# ESP32-S3 register map
Vendor: ESPRESSIF SYSTEMS (SHANGHAI) CO., LTD.; Series: ESP32-S3; File version: 7
CPU: Xtensa LX7 r0p0, little endian, no MPU, FPU, 3 interrupt priority bits
Address unit: 32 bits
Registers are 32-bit, read-write, reset 0x0 unless marked. A register's access mark holds for its fields unless they carry their own. Offsets are from the block's base; [hi:lo] are bit positions; {n}, {i} and the like mark numbered series.

## DMA — DMA (Direct Memory Access) Controller
Base 0x6003F000
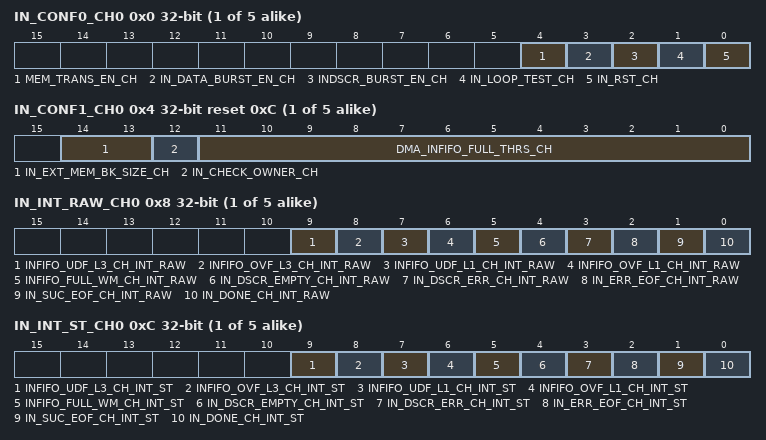
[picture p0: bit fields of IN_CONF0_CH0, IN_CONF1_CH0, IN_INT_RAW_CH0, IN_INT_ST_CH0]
{0x0+0xC0*i} IN_CONF0_CH{i} (i=0..4) — Configure 0 register of Rx channel 0
  [4] MEM_TRANS_EN_CH — Set this bit 1 to enable automatic transmitting data from memory to memory via DMA.
  [3] IN_DATA_BURST_EN_CH — Set this bit to 1 to enable INCR burst transfer for Rx channel 0 receiving data when accessing internal SRAM.
  [2] INDSCR_BURST_EN_CH — Set this bit to 1 to enable INCR burst transfer for Rx channel 0 reading link descriptor when accessing internal SRAM.
  [1] IN_LOOP_TEST_CH — reserved
  [0] IN_RST_CH — This bit is used to reset DMA channel 0 Rx FSM and Rx FIFO pointer.
{0x4+0xC0*i} IN_CONF1_CH{i} (i=0..4) reset 0xC — Configure 1 register of Rx channel 0
  [14:13] IN_EXT_MEM_BK_SIZE_CH — Block size of Rx channel 0 when DMA access external SRAM. 0: 16 bytes 1: 32 bytes 2/3:reserved
  [12] IN_CHECK_OWNER_CH — Set this bit to enable checking the owner attribute of the link descriptor.
  [11:0] DMA_INFIFO_FULL_THRS_CH — This register is used to generate the INFIFO_FULL_WM_INT interrupt when Rx channel 0 received byte number in Rx FIFO is up to the value of the register.
{0x8+0xC0*i} IN_INT_RAW_CH{i} (i=0..4) ro — Raw status interrupt of Rx channel 0
  [9] INFIFO_UDF_L3_CH_INT_RAW — This raw interrupt bit turns to high level when level 3 fifo of Rx channel 0 is underflow.
  [8] INFIFO_OVF_L3_CH_INT_RAW — This raw interrupt bit turns to high level when level 3 fifo of Rx channel 0 is overflow.
  [7] INFIFO_UDF_L1_CH_INT_RAW — This raw interrupt bit turns to high level when level 1 fifo of Rx channel 0 is underflow.
  [6] INFIFO_OVF_L1_CH_INT_RAW — This raw interrupt bit turns to high level when level 1 fifo of Rx channel 0 is overflow.
  [5] INFIFO_FULL_WM_CH_INT_RAW — The raw interrupt bit turns to high level when received data byte number is up to threshold configured by REG_DMA_INFIFO_FULL_THRS_CH0 in Rx FIFO of channel 0.
  [4] IN_DSCR_EMPTY_CH_INT_RAW — The raw interrupt bit turns to high level when Rx buffer pointed by inlink is full and receiving data is not completed, but there is no more inlink for Rx channel 0.
  [3] IN_DSCR_ERR_CH_INT_RAW — The raw interrupt bit turns to high level when detecting inlink descriptor error, including owner error, the second and third word error of inlink descriptor for Rx channel 0.
  [2] IN_ERR_EOF_CH_INT_RAW — The raw interrupt bit turns to high level when data error is detected only in the case that the peripheral is UHCI0 for Rx channel 0. For other peripherals, this raw interrupt is reserved.
  [1] IN_SUC_EOF_CH_INT_RAW — The raw interrupt bit turns to high level when the last data pointed by one inlink descriptor has been received for Rx channel 0. For UHCI0, the raw interrupt bit turns to high level when the last data pointed by one inlink descriptor has been received and no data error is detected for Rx channel 0.
  [0] IN_DONE_CH_INT_RAW — The raw interrupt bit turns to high level when the last data pointed by one inlink descriptor has been received for Rx channel 0.
{0xC+0xC0*i} IN_INT_ST_CH{i} (i=0..4) ro — Masked interrupt of Rx channel 0
  [9] INFIFO_UDF_L3_CH_INT_ST — The raw interrupt status bit for the INFIFO_UDF_L3_CH_INT interrupt.
  [8] INFIFO_OVF_L3_CH_INT_ST — The raw interrupt status bit for the INFIFO_OVF_L3_CH_INT interrupt.
  [7] INFIFO_UDF_L1_CH_INT_ST — The raw interrupt status bit for the INFIFO_UDF_L1_CH_INT interrupt.
  [6] INFIFO_OVF_L1_CH_INT_ST — The raw interrupt status bit for the INFIFO_OVF_L1_CH_INT interrupt.
  [5] INFIFO_FULL_WM_CH_INT_ST — The raw interrupt status bit for the INFIFO_FULL_WM_CH_INT interrupt.
  [4] IN_DSCR_EMPTY_CH_INT_ST — The raw interrupt status bit for the IN_DSCR_EMPTY_CH_INT interrupt.
  [3] IN_DSCR_ERR_CH_INT_ST — The raw interrupt status bit for the IN_DSCR_ERR_CH_INT interrupt.
  [2] IN_ERR_EOF_CH_INT_ST — The raw interrupt status bit for the IN_ERR_EOF_CH_INT interrupt.
  [1] IN_SUC_EOF_CH_INT_ST — The raw interrupt status bit for the IN_SUC_EOF_CH_INT interrupt.
  [0] IN_DONE_CH_INT_ST — The raw interrupt status bit for the IN_DONE_CH_INT interrupt.
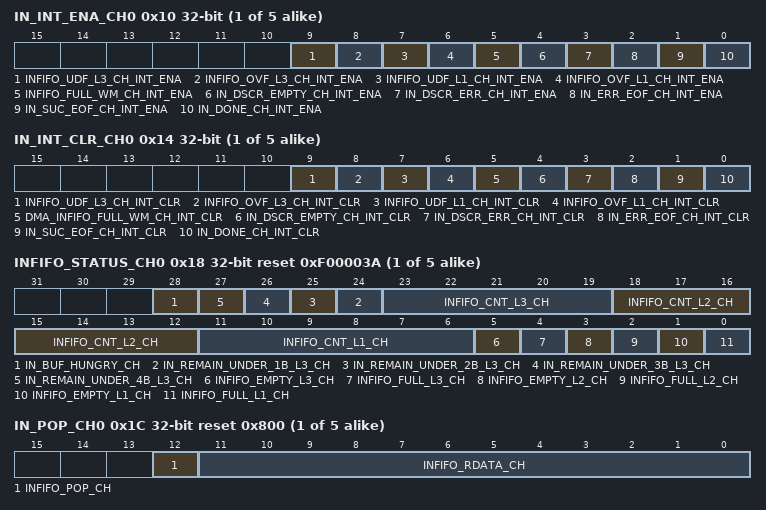
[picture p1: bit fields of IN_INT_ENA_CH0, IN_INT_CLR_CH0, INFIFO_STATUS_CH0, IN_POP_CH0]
{0x10+0xC0*i} IN_INT_ENA_CH{i} (i=0..4) — Interrupt enable bits of Rx channel 0
  [9] INFIFO_UDF_L3_CH_INT_ENA — The interrupt enable bit for the INFIFO_UDF_L3_CH_INT interrupt.
  [8] INFIFO_OVF_L3_CH_INT_ENA — The interrupt enable bit for the INFIFO_OVF_L3_CH_INT interrupt.
  [7] INFIFO_UDF_L1_CH_INT_ENA — The interrupt enable bit for the INFIFO_UDF_L1_CH_INT interrupt.
  [6] INFIFO_OVF_L1_CH_INT_ENA — The interrupt enable bit for the INFIFO_OVF_L1_CH_INT interrupt.
  [5] INFIFO_FULL_WM_CH_INT_ENA — The interrupt enable bit for the INFIFO_FULL_WM_CH_INT interrupt.
  [4] IN_DSCR_EMPTY_CH_INT_ENA — The interrupt enable bit for the IN_DSCR_EMPTY_CH_INT interrupt.
  [3] IN_DSCR_ERR_CH_INT_ENA — The interrupt enable bit for the IN_DSCR_ERR_CH_INT interrupt.
  [2] IN_ERR_EOF_CH_INT_ENA — The interrupt enable bit for the IN_ERR_EOF_CH_INT interrupt.
  [1] IN_SUC_EOF_CH_INT_ENA — The interrupt enable bit for the IN_SUC_EOF_CH_INT interrupt.
  [0] IN_DONE_CH_INT_ENA — The interrupt enable bit for the IN_DONE_CH_INT interrupt.
{0x14+0xC0*i} IN_INT_CLR_CH{i} (i=0..4) wo — Interrupt clear bits of Rx channel 0
  [9] INFIFO_UDF_L3_CH_INT_CLR — Set this bit to clear the INFIFO_UDF_L3_CH_INT interrupt.
  [8] INFIFO_OVF_L3_CH_INT_CLR — Set this bit to clear the INFIFO_OVF_L3_CH_INT interrupt.
  [7] INFIFO_UDF_L1_CH_INT_CLR — Set this bit to clear the INFIFO_UDF_L1_CH_INT interrupt.
  [6] INFIFO_OVF_L1_CH_INT_CLR — Set this bit to clear the INFIFO_OVF_L1_CH_INT interrupt.
  [5] DMA_INFIFO_FULL_WM_CH_INT_CLR — Set this bit to clear the INFIFO_FULL_WM_CH_INT interrupt.
  [4] IN_DSCR_EMPTY_CH_INT_CLR — Set this bit to clear the IN_DSCR_EMPTY_CH_INT interrupt.
  [3] IN_DSCR_ERR_CH_INT_CLR — Set this bit to clear the IN_DSCR_ERR_CH_INT interrupt.
  [2] IN_ERR_EOF_CH_INT_CLR — Set this bit to clear the IN_ERR_EOF_CH_INT interrupt.
  [1] IN_SUC_EOF_CH_INT_CLR — Set this bit to clear the IN_SUC_EOF_CH_INT interrupt.
  [0] IN_DONE_CH_INT_CLR — Set this bit to clear the IN_DONE_CH_INT interrupt.
{0x18+0xC0*i} INFIFO_STATUS_CH{i} (i=0..4) ro reset 0xF00003A — Receive FIFO status of Rx channel 0
  [28] IN_BUF_HUNGRY_CH — reserved
  [n+23] IN_REMAIN_UNDER_{n}B_L3_CH (n=1..4) — reserved
  [23:19] INFIFO_CNT_L3_CH — The register stores the byte number of the data in L3 Rx FIFO for Rx channel 0.
  [18:12] INFIFO_CNT_L2_CH — The register stores the byte number of the data in L2 Rx FIFO for Rx channel 0.
  [11:6] INFIFO_CNT_L1_CH — The register stores the byte number of the data in L1 Rx FIFO for Rx channel 0.
  [5] INFIFO_EMPTY_L3_CH — L3 Rx FIFO empty signal for Rx channel 0.
  [4] INFIFO_FULL_L3_CH — L3 Rx FIFO full signal for Rx channel 0.
  [3] INFIFO_EMPTY_L2_CH — L2 Rx FIFO empty signal for Rx channel 0.
  [2] INFIFO_FULL_L2_CH — L2 Rx FIFO full signal for Rx channel 0.
  [1] INFIFO_EMPTY_L1_CH — L1 Rx FIFO empty signal for Rx channel 0.
  [0] INFIFO_FULL_L1_CH — L1 Rx FIFO full signal for Rx channel 0.
{0x1C+0xC0*i} IN_POP_CH{i} (i=0..4) access per field reset 0x800 — Pop control register of Rx channel 0
  [12] INFIFO_POP_CH rw — Set this bit to pop data from DMA FIFO.
  [11:0] INFIFO_RDATA_CH ro — This register stores the data popping from DMA FIFO.
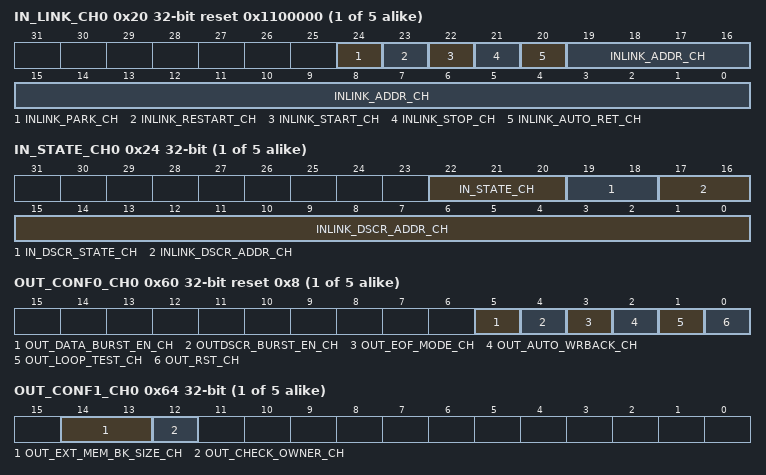
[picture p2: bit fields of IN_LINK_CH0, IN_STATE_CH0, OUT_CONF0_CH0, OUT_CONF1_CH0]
{0x20+0xC0*i} IN_LINK_CH{i} (i=0..4) access per field reset 0x1100000 — Link descriptor configure and control register of Rx channel 0
  [24] INLINK_PARK_CH ro — 1: the inlink descriptor's FSM is in idle state. 0: the inlink descriptor's FSM is working.
  [23] INLINK_RESTART_CH rw — Set this bit to mount a new inlink descriptor.
  [22] INLINK_START_CH rw — Set this bit to start dealing with the inlink descriptors.
  [21] INLINK_STOP_CH rw — Set this bit to stop dealing with the inlink descriptors.
  [20] INLINK_AUTO_RET_CH rw — Set this bit to return to current inlink descriptor's address, when there are some errors in current receiving data.
  [19:0] INLINK_ADDR_CH rw — This register stores the 20 least significant bits of the first inlink descriptor's address.
{0x24+0xC0*i} IN_STATE_CH{i} (i=0..4) ro — Receive status of Rx channel 0
  [22:20] IN_STATE_CH — reserved
  [19:18] IN_DSCR_STATE_CH — reserved
  [17:0] INLINK_DSCR_ADDR_CH — This register stores the current inlink descriptor's address.
{0x28+0xC0*i} IN_SUC_EOF_DES_ADDR_CH{i} (i=0..4) ro — Inlink descriptor address when EOF occurs of Rx channel 0
  [31:0] IN_SUC_EOF_DES_ADDR_CH — This register stores the address of the inlink descriptor when the EOF bit in this descriptor is 1.
{0x2C+0xC0*i} IN_ERR_EOF_DES_ADDR_CH{i} (i=0..4) ro — Inlink descriptor address when errors occur of Rx channel 0
  [31:0] IN_ERR_EOF_DES_ADDR_CH — This register stores the address of the inlink descriptor when there are some errors in current receiving data. Only used when peripheral is UHCI0.
{0x30+0xC0*i} IN_DSCR_CH{i} (i=0..4) ro — Current inlink descriptor address of Rx channel 0
  [31:0] INLINK_DSCR_CH — The address of the current inlink descriptor x.
{0x34+0xC0*i} IN_DSCR_BF0_CH{i} (i=0..4) ro — The last inlink descriptor address of Rx channel 0
  [31:0] INLINK_DSCR_BF0_CH — The address of the last inlink descriptor x-1.
{0x38+0xC0*i} IN_DSCR_BF1_CH{i} (i=0..4) ro — The second-to-last inlink descriptor address of Rx channel 0
  [31:0] INLINK_DSCR_BF1_CH — The address of the second-to-last inlink descriptor x-2.
{0x3C+0xC0*i} IN_WIGHT_CH{i} (i=0..4) reset 0xF00 — Weight register of Rx channel 0
  [11:8] RX_WEIGHT_CH — The weight of Rx channel 0.
{0x44+0xC0*i} IN_PRI_CH{i} (i=0..4) — Priority register of Rx channel 0
  [3:0] RX_PRI_CH — The priority of Rx channel 0. The larger of the value, the higher of the priority.
{0x48+0xC0*i} IN_PERI_SEL_CH{i} (i=0..4) reset 0x3F — Peripheral selection of Rx channel 0
  [5:0] PERI_IN_SEL_CH — This register is used to select peripheral for Rx channel 0. 0:SPI2. 1: SPI3. 2: UHCI0. 3: I2S0. 4: I2S1. 5: LCD_CAM. 6: AES. 7: SHA. 8: ADC_DAC. 9: RMT.
{0x60+0xC0*i} OUT_CONF0_CH{i} (i=0..4) reset 0x8 — Configure 0 register of Tx channel 0
  [5] OUT_DATA_BURST_EN_CH — Set this bit to 1 to enable INCR burst transfer for Tx channel 0 transmitting data when accessing internal SRAM.
  [4] OUTDSCR_BURST_EN_CH — Set this bit to 1 to enable INCR burst transfer for Tx channel 0 reading link descriptor when accessing internal SRAM.
  [3] OUT_EOF_MODE_CH — EOF flag generation mode when transmitting data. 1: EOF flag for Tx channel 0 is generated when data need to transmit has been popped from FIFO in DMA
  [2] OUT_AUTO_WRBACK_CH — Set this bit to enable automatic outlink-writeback when all the data in tx buffer has been transmitted.
  [1] OUT_LOOP_TEST_CH — reserved
  [0] OUT_RST_CH — This bit is used to reset DMA channel 0 Tx FSM and Tx FIFO pointer.
{0x64+0xC0*i} OUT_CONF1_CH{i} (i=0..4) — Configure 1 register of Tx channel 0
  [14:13] OUT_EXT_MEM_BK_SIZE_CH — Block size of Tx channel 0 when DMA access external SRAM. 0: 16 bytes 1: 32 bytes 2/3:reserved
  [12] OUT_CHECK_OWNER_CH — Set this bit to enable checking the owner attribute of the link descriptor.
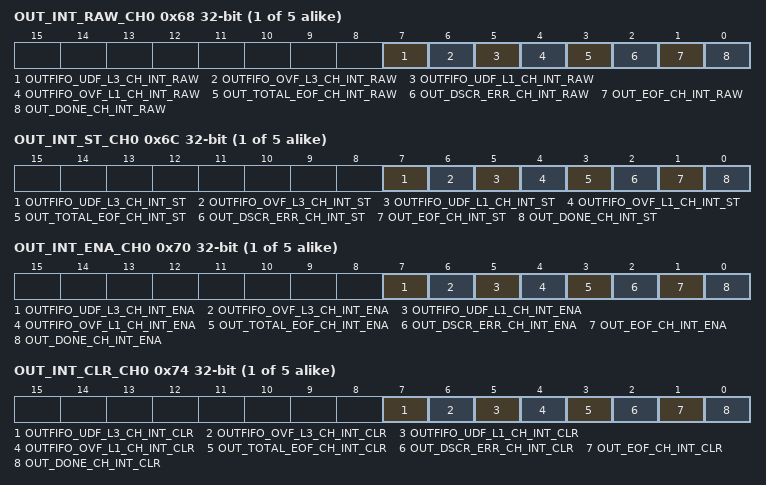
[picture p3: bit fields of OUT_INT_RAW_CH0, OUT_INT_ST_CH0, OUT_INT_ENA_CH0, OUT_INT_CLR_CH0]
{0x68+0xC0*i} OUT_INT_RAW_CH{i} (i=0..4) ro — Raw status interrupt of Tx channel 0
  [7] OUTFIFO_UDF_L3_CH_INT_RAW — This raw interrupt bit turns to high level when level 3 fifo of Tx channel 0 is underflow.
  [6] OUTFIFO_OVF_L3_CH_INT_RAW — This raw interrupt bit turns to high level when level 3 fifo of Tx channel 0 is overflow.
  [5] OUTFIFO_UDF_L1_CH_INT_RAW — This raw interrupt bit turns to high level when level 1 fifo of Tx channel 0 is underflow.
  [4] OUTFIFO_OVF_L1_CH_INT_RAW — This raw interrupt bit turns to high level when level 1 fifo of Tx channel 0 is overflow.
  [3] OUT_TOTAL_EOF_CH_INT_RAW — The raw interrupt bit turns to high level when data corresponding a outlink (includes one link descriptor or few link descriptors) is transmitted out for Tx channel 0.
  [2] OUT_DSCR_ERR_CH_INT_RAW — The raw interrupt bit turns to high level when detecting outlink descriptor error, including owner error, the second and third word error of outlink descriptor for Tx channel 0.
  [1] OUT_EOF_CH_INT_RAW — The raw interrupt bit turns to high level when the last data pointed by one outlink descriptor has been read from memory for Tx channel 0.
  [0] OUT_DONE_CH_INT_RAW — The raw interrupt bit turns to high level when the last data pointed by one outlink descriptor has been transmitted to peripherals for Tx channel 0.
{0x6C+0xC0*i} OUT_INT_ST_CH{i} (i=0..4) ro — Masked interrupt of Tx channel 0
  [7] OUTFIFO_UDF_L3_CH_INT_ST — The raw interrupt status bit for the OUTFIFO_UDF_L3_CH_INT interrupt.
  [6] OUTFIFO_OVF_L3_CH_INT_ST — The raw interrupt status bit for the OUTFIFO_OVF_L3_CH_INT interrupt.
  [5] OUTFIFO_UDF_L1_CH_INT_ST — The raw interrupt status bit for the OUTFIFO_UDF_L1_CH_INT interrupt.
  [4] OUTFIFO_OVF_L1_CH_INT_ST — The raw interrupt status bit for the OUTFIFO_OVF_L1_CH_INT interrupt.
  [3] OUT_TOTAL_EOF_CH_INT_ST — The raw interrupt status bit for the OUT_TOTAL_EOF_CH_INT interrupt.
  [2] OUT_DSCR_ERR_CH_INT_ST — The raw interrupt status bit for the OUT_DSCR_ERR_CH_INT interrupt.
  [1] OUT_EOF_CH_INT_ST — The raw interrupt status bit for the OUT_EOF_CH_INT interrupt.
  [0] OUT_DONE_CH_INT_ST — The raw interrupt status bit for the OUT_DONE_CH_INT interrupt.
{0x70+0xC0*i} OUT_INT_ENA_CH{i} (i=0..4) — Interrupt enable bits of Tx channel 0
  [7] OUTFIFO_UDF_L3_CH_INT_ENA — The interrupt enable bit for the OUTFIFO_UDF_L3_CH_INT interrupt.
  [6] OUTFIFO_OVF_L3_CH_INT_ENA — The interrupt enable bit for the OUTFIFO_OVF_L3_CH_INT interrupt.
  [5] OUTFIFO_UDF_L1_CH_INT_ENA — The interrupt enable bit for the OUTFIFO_UDF_L1_CH_INT interrupt.
  [4] OUTFIFO_OVF_L1_CH_INT_ENA — The interrupt enable bit for the OUTFIFO_OVF_L1_CH_INT interrupt.
  [3] OUT_TOTAL_EOF_CH_INT_ENA — The interrupt enable bit for the OUT_TOTAL_EOF_CH_INT interrupt.
  [2] OUT_DSCR_ERR_CH_INT_ENA — The interrupt enable bit for the OUT_DSCR_ERR_CH_INT interrupt.
  [1] OUT_EOF_CH_INT_ENA — The interrupt enable bit for the OUT_EOF_CH_INT interrupt.
  [0] OUT_DONE_CH_INT_ENA — The interrupt enable bit for the OUT_DONE_CH_INT interrupt.
{0x74+0xC0*i} OUT_INT_CLR_CH{i} (i=0..4) wo — Interrupt clear bits of Tx channel 0
  [7] OUTFIFO_UDF_L3_CH_INT_CLR — Set this bit to clear the OUTFIFO_UDF_L3_CH_INT interrupt.
  [6] OUTFIFO_OVF_L3_CH_INT_CLR — Set this bit to clear the OUTFIFO_OVF_L3_CH_INT interrupt.
  [5] OUTFIFO_UDF_L1_CH_INT_CLR — Set this bit to clear the OUTFIFO_UDF_L1_CH_INT interrupt.
  [4] OUTFIFO_OVF_L1_CH_INT_CLR — Set this bit to clear the OUTFIFO_OVF_L1_CH_INT interrupt.
  [3] OUT_TOTAL_EOF_CH_INT_CLR — Set this bit to clear the OUT_TOTAL_EOF_CH_INT interrupt.
  [2] OUT_DSCR_ERR_CH_INT_CLR — Set this bit to clear the OUT_DSCR_ERR_CH_INT interrupt.
  [1] OUT_EOF_CH_INT_CLR — Set this bit to clear the OUT_EOF_CH_INT interrupt.
  [0] OUT_DONE_CH_INT_CLR — Set this bit to clear the OUT_DONE_CH_INT interrupt.
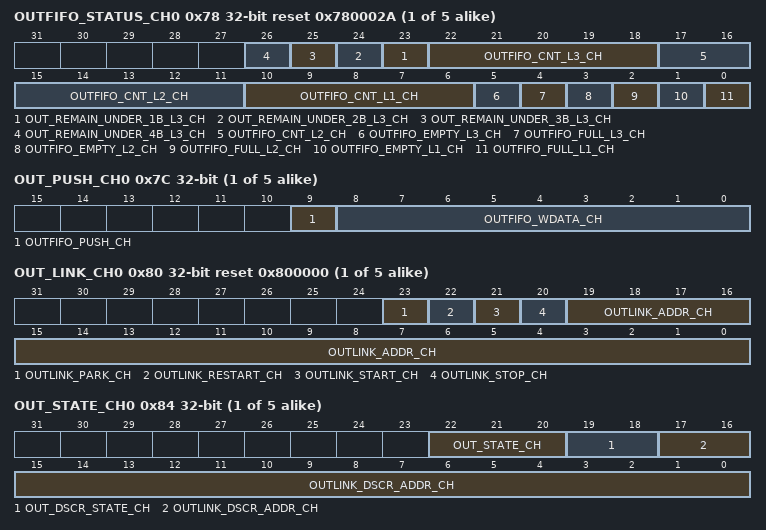
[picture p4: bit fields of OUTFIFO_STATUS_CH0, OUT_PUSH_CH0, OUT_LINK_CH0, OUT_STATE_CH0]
{0x78+0xC0*i} OUTFIFO_STATUS_CH{i} (i=0..4) ro reset 0x780002A — Transmit FIFO status of Tx channel 0
  [n+22] OUT_REMAIN_UNDER_{n}B_L3_CH (n=1..4) — reserved
  [22:18] OUTFIFO_CNT_L3_CH — The register stores the byte number of the data in L3 Tx FIFO for Tx channel 0.
  [17:11] OUTFIFO_CNT_L2_CH — The register stores the byte number of the data in L2 Tx FIFO for Tx channel 0.
  [10:6] OUTFIFO_CNT_L1_CH — The register stores the byte number of the data in L1 Tx FIFO for Tx channel 0.
  [5] OUTFIFO_EMPTY_L3_CH — L3 Tx FIFO empty signal for Tx channel 0.
  [4] OUTFIFO_FULL_L3_CH — L3 Tx FIFO full signal for Tx channel 0.
  [3] OUTFIFO_EMPTY_L2_CH — L2 Tx FIFO empty signal for Tx channel 0.
  [2] OUTFIFO_FULL_L2_CH — L2 Tx FIFO full signal for Tx channel 0.
  [1] OUTFIFO_EMPTY_L1_CH — L1 Tx FIFO empty signal for Tx channel 0.
  [0] OUTFIFO_FULL_L1_CH — L1 Tx FIFO full signal for Tx channel 0.
{0x7C+0xC0*i} OUT_PUSH_CH{i} (i=0..4) — Push control register of Rx channel 0
  [9] OUTFIFO_PUSH_CH — Set this bit to push data into DMA FIFO.
  [8:0] OUTFIFO_WDATA_CH — This register stores the data that need to be pushed into DMA FIFO.
{0x80+0xC0*i} OUT_LINK_CH{i} (i=0..4) access per field reset 0x800000 — Link descriptor configure and control register of Tx channel 0
  [23] OUTLINK_PARK_CH ro — 1: the outlink descriptor's FSM is in idle state. 0: the outlink descriptor's FSM is working.
  [22] OUTLINK_RESTART_CH rw — Set this bit to restart a new outlink from the last address.
  [21] OUTLINK_START_CH rw — Set this bit to start dealing with the outlink descriptors.
  [20] OUTLINK_STOP_CH rw — Set this bit to stop dealing with the outlink descriptors.
  [19:0] OUTLINK_ADDR_CH rw — This register stores the 20 least significant bits of the first outlink descriptor's address.
{0x84+0xC0*i} OUT_STATE_CH{i} (i=0..4) ro — Transmit status of Tx channel 0
  [22:20] OUT_STATE_CH — reserved
  [19:18] OUT_DSCR_STATE_CH — reserved
  [17:0] OUTLINK_DSCR_ADDR_CH — This register stores the current outlink descriptor's address.
{0x88+0xC0*i} OUT_EOF_DES_ADDR_CH{i} (i=0..4) ro — Outlink descriptor address when EOF occurs of Tx channel 0
  [31:0] OUT_EOF_DES_ADDR_CH — This register stores the address of the outlink descriptor when the EOF bit in this descriptor is 1.
{0x8C+0xC0*i} OUT_EOF_BFR_DES_ADDR_CH{i} (i=0..4) ro — The last outlink descriptor address when EOF occurs of Tx channel 0
  [31:0] OUT_EOF_BFR_DES_ADDR_CH — This register stores the address of the outlink descriptor before the last outlink descriptor.
{0x90+0xC0*i} OUT_DSCR_CH{i} (i=0..4) ro — Current inlink descriptor address of Tx channel 0
  [31:0] OUTLINK_DSCR_CH — The address of the current outlink descriptor y.
{0x94+0xC0*i} OUT_DSCR_BF0_CH{i} (i=0..4) ro — The last inlink descriptor address of Tx channel 0
  [31:0] OUTLINK_DSCR_BF0_CH — The address of the last outlink descriptor y-1.
{0x98+0xC0*i} OUT_DSCR_BF1_CH{i} (i=0..4) ro — The second-to-last inlink descriptor address of Tx channel 0
  [31:0] OUTLINK_DSCR_BF1_CH — The address of the second-to-last inlink descriptor x-2.
{0x9C+0xC0*i} OUT_WIGHT_CH{i} (i=0..4) reset 0xF00 — Weight register of Rx channel 0
  [11:8] TX_WEIGHT_CH — The weight of Tx channel 0.
{0xA4+0xC0*i} OUT_PRI_CH{i} (i=0..4) — Priority register of Tx channel 0.
  [3:0] TX_PRI_CH — The priority of Tx channel 0. The larger of the value, the higher of the priority.
{0xA8+0xC0*i} OUT_PERI_SEL_CH{i} (i=0..4) reset 0x3F — Peripheral selection of Tx channel 0
  [5:0] PERI_OUT_SEL_CH — This register is used to select peripheral for Tx channel 0. 0:SPI2. 1: SPI3. 2: UHCI0. 3: I2S0. 4: I2S1. 5: LCD_CAM. 6: AES. 7: SHA. 8: ADC_DAC. 9: RMT.
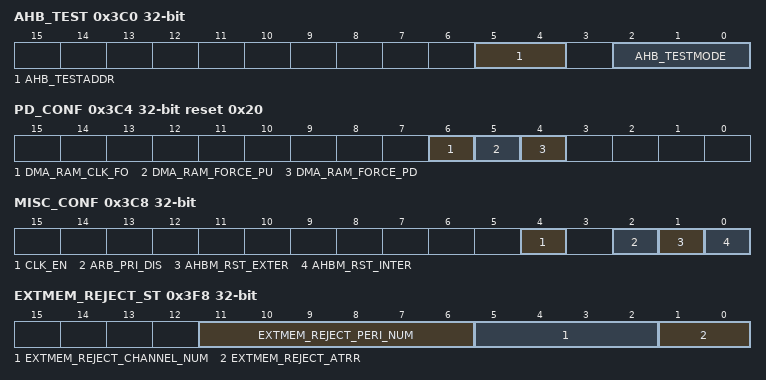
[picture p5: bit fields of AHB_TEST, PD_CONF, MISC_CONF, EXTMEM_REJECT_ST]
0x3C0 AHB_TEST — reserved
  [5:4] AHB_TESTADDR — reserved
  [2:0] AHB_TESTMODE — reserved
0x3C4 PD_CONF reset 0x20 — reserved
  [6] DMA_RAM_CLK_FO — 1: Force to open the clock and bypass the gate-clock when accessing the RAM in DMA. 0: A gate-clock will be used when accessing the RAM in DMA.
  [5] DMA_RAM_FORCE_PU — Set this bit to force power up DMA internal memory
  [4] DMA_RAM_FORCE_PD — Set this bit to force power down DMA internal memory.
0x3C8 MISC_CONF — MISC register
  [4] CLK_EN — 1'h1: Force clock on for register. 1'h0: Support clock only when application writes registers.
  [2] ARB_PRI_DIS — Set this bit to disable priority arbitration function.
  [1] AHBM_RST_EXTER — Set this bit, then clear this bit to reset the external ahb FSM.
  [0] AHBM_RST_INTER — Set this bit, then clear this bit to reset the internal ahb FSM.
{0x3CC+8i} IN_SRAM_SIZE_CH{i} (i=0..4) reset 0xE — Receive L2 FIFO depth of Rx channel 0
  [6:0] IN_SIZE_CH — This register is used to configure the size of L2 Tx FIFO for Rx channel 0. 0:16 bytes. 1:24 bytes. 2:32 bytes. 3: 40 bytes. 4: 48 bytes. 5:56 bytes. 6: 64 bytes. 7: 72 bytes. 8: 80 bytes.
{0x3D0+8i} OUT_SRAM_SIZE_CH{i} (i=0..4) reset 0xE — Transmit L2 FIFO depth of Tx channel 0
  [6:0] OUT_SIZE_CH — This register is used to configure the size of L2 Tx FIFO for Tx channel 0. 0:16 bytes. 1:24 bytes. 2:32 bytes. 3: 40 bytes. 4: 48 bytes. 5:56 bytes. 6: 64 bytes. 7: 72 bytes. 8: 80 bytes.
0x3F4 EXTMEM_REJECT_ADDR ro — Reject address accessing external RAM
  [31:0] EXTMEM_REJECT_ADDR — This register store the first address rejected by permission control when accessing external RAM.
0x3F8 EXTMEM_REJECT_ST ro — Reject status accessing external RAM
  [11:6] EXTMEM_REJECT_PERI_NUM — This register indicate reject accessing from which peripheral.
  [5:2] EXTMEM_REJECT_CHANNEL_NUM — The register indicate the reject accessing from which channel.
  [1:0] EXTMEM_REJECT_ATRR — The reject accessing. Bit 0: if this bit is 1, the rejected accessing is READ. Bit 1: if this bit is 1, the rejected accessing is WRITE.
0x3FC EXTMEM_REJECT_INT_RAW ro — Raw interrupt status of external RAM permission
  [0] EXTMEM_REJECT_INT_RAW — The raw interrupt bit turns to high level when accessing external RAM is rejected by permission control.
0x400 EXTMEM_REJECT_INT_ST ro — Masked interrupt status of external RAM permission
  [0] EXTMEM_REJECT_INT_ST — The raw interrupt status bit for the EXTMEM_REJECT_INT interrupt.
0x404 EXTMEM_REJECT_INT_ENA — Interrupt enable bits of external RAM permission
  [0] EXTMEM_REJECT_INT_ENA — The interrupt enable bit for the EXTMEM_REJECT_INT interrupt.
0x408 EXTMEM_REJECT_INT_CLR wo — Interrupt clear bits of external RAM permission
  [0] EXTMEM_REJECT_INT_CLR — Set this bit to clear the EXTMEM_REJECT_INT interrupt.
0x40C DATE reset 0x2101180 — Version control register
  [31:0] DATE — register version.
